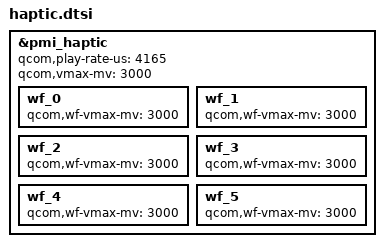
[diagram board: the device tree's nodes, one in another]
/* Haptics */
&pmi_haptic{
	qcom,play-rate-us = <4165>;
	qcom,vmax-mv = <3000>;
	wf_0 { qcom,wf-vmax-mv = <3000>; };
	wf_1 { qcom,wf-vmax-mv = <3000>; };
	wf_2 { qcom,wf-vmax-mv = <3000>; };
	wf_3 { qcom,wf-vmax-mv = <3000>; };
	wf_4 { qcom,wf-vmax-mv = <3000>; };
	wf_5 { qcom,wf-vmax-mv = <3000>; };
};
